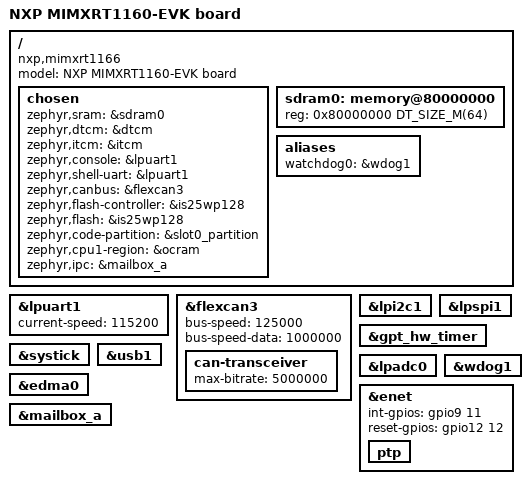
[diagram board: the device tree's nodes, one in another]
/*
 * Copyright (c) 2021, NXP
 *
 * SPDX-License-Identifier: Apache-2.0
 */

/dts-v1/;

#include <nxp/nxp_rt11xx_cm7.dtsi>
#include "mimxrt1160_evk.dtsi"

/ {
	model = "NXP MIMXRT1160-EVK board";
	compatible = "nxp,mimxrt1166";

	chosen {
		zephyr,sram = &sdram0;
		zephyr,dtcm = &dtcm;
		zephyr,itcm = &itcm;
		zephyr,console = &lpuart1;
		zephyr,shell-uart = &lpuart1;
		zephyr,canbus = &flexcan3;
		zephyr,flash-controller = &is25wp128;
		zephyr,flash = &is25wp128;
		zephyr,code-partition = &slot0_partition;
		zephyr,cpu1-region = &ocram;
		zephyr,ipc = &mailbox_a;
	};

	sdram0: memory@80000000 {
		/* Winbond W9825G6KH-5I */
		device_type = "memory";
		reg = <0x80000000 DT_SIZE_M(64)>;
	};

	aliases {
		watchdog0 = &wdog1;
	};
};

&lpuart1 {
	status = "okay";
	current-speed = <115200>;
};

&flexcan3 {
	status = "okay";
	bus-speed = <125000>;
	bus-speed-data = <1000000>;
	can-transceiver {
		max-bitrate = <5000000>;
	};
};

&lpi2c1 {
	status = "okay";
};

&lpspi1 {
	status = "okay";
};

/* GPT and Systick are enabled. If power management is enabled, the GPT
 * timer will be used instead of systick, as allows the core clock to
 * be gated.
 */
&gpt_hw_timer {
	status = "okay";
};

&systick {
	status = "okay";
};

&lpadc0 {
	status = "okay";
};

&wdog1 {
	status = "okay";
};

&edma0 {
	status = "okay";
};

&enet {
	status = "okay";
	int-gpios = <&gpio9 11 GPIO_ACTIVE_HIGH>;
	reset-gpios = <&gpio12 12 GPIO_ACTIVE_HIGH>;
	ptp {
		status = "okay";
	};
};

zephyr_udc0: &usb1 {
	status = "okay";
};

&mailbox_a {
	status = "okay";
};
